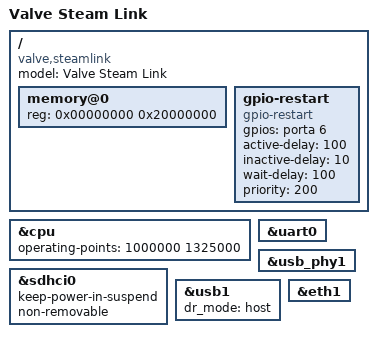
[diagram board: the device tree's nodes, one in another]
/dts-v1/;

#include "berlin2cd.dtsi"
#include <dt-bindings/gpio/gpio.h>

/ {
	model = "Valve Steam Link";
	compatible = "valve,steamlink", "marvell,berlin2cd", "marvell,berlin";

	memory@0 {
		device_type = "memory";
		reg = <0x00000000 0x20000000>; /* 512 MB */
	};

	gpio-restart {
		compatible = "gpio-restart";
		gpios = <&porta 6 GPIO_ACTIVE_HIGH>;
		active-delay = <100>;
		inactive-delay = <10>;
		wait-delay = <100>;
		priority = <200>;
	};
};

&cpu {
	operating-points = <
		/* kHz    uV */
		1000000 1325000
	>;
};

/* Fixed interface to on-board Marvell 8897 Wi-Fi/Bluetooth/NFC chip. */
&sdhci0 {
	keep-power-in-suspend;
	non-removable;
	status = "okay";
};

&uart0 {
	/* RX/TX are routed to TP50/TP51 on the board. */
	status = "okay";
};

/* The SoC is connected to on-board USB hub, with one downstream port wired
 * to the on-board Steam Controller wireless receiver chip. */
&usb_phy1 { status = "okay"; };

&usb1 {
	dr_mode = "host";
	status = "okay";
};

&eth1 { status = "okay"; };
